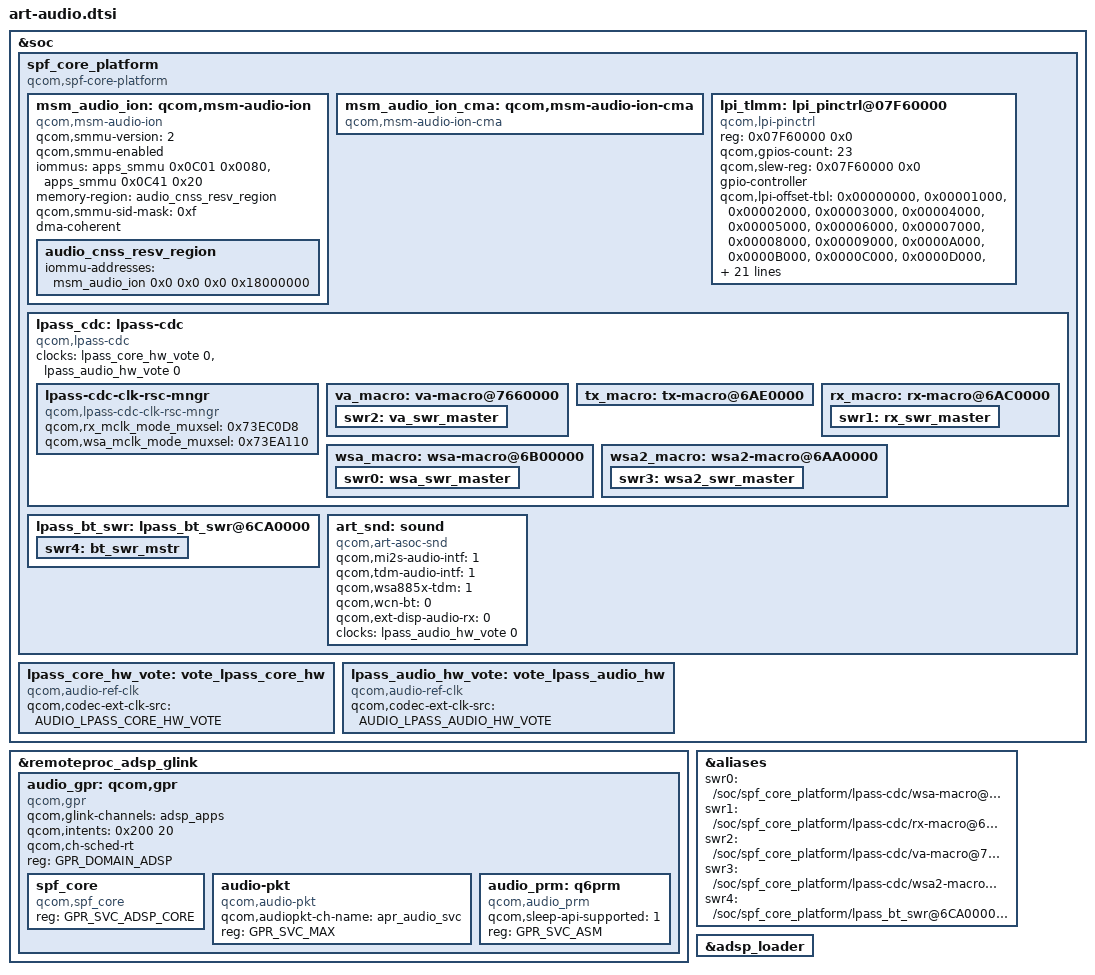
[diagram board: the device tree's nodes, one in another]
/*
 * Copyright (c) Qualcomm Technologies, Inc. and/or its subsidiaries.
 * SPDX-License-Identifier: BSD-3-Clause-Clear
*/

#include <bindings/qcom,audio-ext-clk.h>
#include <bindings/qcom,gpr.h>
#include "msm-audio-lpass.dtsi"

&soc {
	spf_core_platform: spf_core_platform {
		compatible = "qcom,spf-core-platform";
	};

	lpass_core_hw_vote: vote_lpass_core_hw {
		compatible = "qcom,audio-ref-clk";
		qcom,codec-ext-clk-src = <AUDIO_LPASS_CORE_HW_VOTE>;
		#clock-cells = <1>;
	};

	lpass_audio_hw_vote: vote_lpass_audio_hw {
		compatible = "qcom,audio-ref-clk";
		qcom,codec-ext-clk-src = <AUDIO_LPASS_AUDIO_HW_VOTE>;
		#clock-cells = <1>;
	};
};

&remoteproc_adsp_glink {
	audio_gpr: qcom,gpr {
		compatible = "qcom,gpr";
		qcom,glink-channels = "adsp_apps";
		qcom,intents = <0x200 20>;
		qcom,ch-sched-rt;
		reg = <GPR_DOMAIN_ADSP>;

		spf_core {
			compatible = "qcom,spf_core";
			reg = <GPR_SVC_ADSP_CORE>;
		};

		audio-pkt {
			compatible = "qcom,audio-pkt";
			qcom,audiopkt-ch-name = "apr_audio_svc";
			reg = <GPR_SVC_MAX>;
		};

		audio_prm: q6prm {
			compatible = "qcom,audio_prm";
			qcom,sleep-api-supported = <1>;
			reg = <GPR_SVC_ASM>;
		};
	};
};

&spf_core_platform {
	#address-cells = <2>;
	#size-cells = <2>;
	msm_audio_ion: qcom,msm-audio-ion {
		compatible = "qcom,msm-audio-ion";
		qcom,smmu-version = <2>;
		qcom,smmu-enabled;
		iommus = <&apps_smmu 0x0C01 0x0080>, <&apps_smmu 0x0C41 0x20>;
		memory-region = <&audio_cnss_resv_region>;
		qcom,smmu-sid-mask = /bits/ 64 <0xf>;
		dma-coherent;

		audio_cnss_resv_region: audio_cnss_resv_region {
			iommu-addresses = <&msm_audio_ion 0x0 0x0 0x0 0x18000000>;
		};
	};

	msm_audio_ion_cma: qcom,msm-audio-ion-cma {
		compatible = "qcom,msm-audio-ion-cma";
	};

	lpi_tlmm: lpi_pinctrl@07F60000 {
		compatible = "qcom,lpi-pinctrl";
		reg = <0x07F60000 0x0>;
		qcom,gpios-count = <23>;
		qcom,slew-reg = <0x07F60000 0x0>;
		gpio-controller;
		#gpio-cells = <2>;
		qcom,lpi-offset-tbl = <0x00000000>, <0x00001000>,
					<0x00002000>, <0x00003000>,
					<0x00004000>, <0x00005000>,
					<0x00006000>, <0x00007000>,
					<0x00008000>, <0x00009000>,
					<0x0000A000>, <0x0000B000>,
					<0x0000C000>, <0x0000D000>,
					<0x0000E000>, <0x0000F000>,
					<0x00010000>, <0x00011000>,
					<0x00012000>, <0x00013000>,
					<0x00014000>, <0x00015000>,
					<0x00016000>;
		qcom,lpi-slew-offset-tbl = <0x0000000B>, <0x0000000B>,
						<0x0000000B>, <0x0000000B>,
						<0x0000000B>, <0x0000000B>,
						<0x0000000B>, <0x0000000B>,
						<0x0000000B>, <0x0000000B>,
						<0x0000000B>, <0x0000000B>,
						<0x0000000B>, <0x0000000B>,
						<0x0000000B>, <0x0000000B>,
						<0x0000000B>, <0x0000000B>,
						<0x0000000B>, <0x0000000B>,
						<0x0000000B>, <0x0000000B>,
						<0x0000000B>;

		qcom,lpi-slew-base-tbl = <0x7F60000>, <0x7F61000>,
						<0x7F62000>, <0x7F63000>,
						<0x7F64000>, <0x7F65000>,
						<0x7F66000>, <0x7F67000>,
						<0x7F68000>, <0x7F69000>,
						<0x7F6A000>, <0x7F6B000>,
						<0x7F6C000>, <0x7F6D000>,
						<0x7F6E000>, <0x7F6F000>,
						<0x7F70000>, <0x7F71000>,
						<0x7F72000>, <0x7F73000>,
						<0x7F74000>, <0x7F75000>,
						<0x7F76000>;

		clock-names = "lpass_core_hw_vote",
				"lpass_audio_hw_vote";
		clocks = <&lpass_core_hw_vote 0>,
				<&lpass_audio_hw_vote 0>;
	};

	lpass_cdc: lpass-cdc {
		compatible = "qcom,lpass-cdc";
		clock-names = "lpass_core_hw_vote",
				"lpass_audio_hw_vote";
		clocks = <&lpass_core_hw_vote 0>,
				<&lpass_audio_hw_vote 0>;
		lpass-cdc-clk-rsc-mngr {
			qcom,rx_mclk_mode_muxsel = <0x73EC0D8>;
			qcom,wsa_mclk_mode_muxsel = <0x73EA110>;
			compatible = "qcom,lpass-cdc-clk-rsc-mngr";
		};

		va_macro: va-macro@7660000 {
			swr2: va_swr_master {
			};
		};

		tx_macro: tx-macro@6AE0000 {
		};

		rx_macro: rx-macro@6AC0000 {
			swr1: rx_swr_master {
			};
		};

		wsa_macro: wsa-macro@6B00000 {
			swr0: wsa_swr_master {
			};
		};

		wsa2_macro: wsa2-macro@6AA0000 {
			swr3: wsa2_swr_master {
			};
		};
	};

	lpass_bt_swr: lpass_bt_swr@6CA0000 {
		swr4: bt_swr_mstr {
		};
	};

	art_snd: sound {
		compatible = "qcom,art-asoc-snd";
		qcom,mi2s-audio-intf = <1>;
		qcom,tdm-audio-intf = <1>;
		qcom,wsa885x-tdm = <1>;
		qcom,wcn-bt = <0>;
		qcom,ext-disp-audio-rx = <0>;
		clock-names = "lpass_audio_hw_vote";
		clocks = <&lpass_audio_hw_vote 0>;
	};
};

&aliases {
	swr0 = "/soc/spf_core_platform/lpass-cdc/wsa-macro@6B00000/wsa_swr_master";
	swr1 = "/soc/spf_core_platform/lpass-cdc/rx-macro@6AC0000/rx_swr_master";
	swr2 = "/soc/spf_core_platform/lpass-cdc/va-macro@7660000/va_swr_master";
	swr3 = "/soc/spf_core_platform/lpass-cdc/wsa2-macro@6AA0000/wsa2_swr_master";
	swr4 = "/soc/spf_core_platform/lpass_bt_swr@6CA0000/bt_swr_mstr";
};

&adsp_loader {
	/delete-property/ qcom,adsp-state;
};
